# STM32F101_iown register map
Vendor: iown-homecontrol; Series: CM3; File version: 1.3
CPU: CM3 r1p1, little endian, no MPU, no FPU, VTOR, 4 interrupt priority bits
Registers are 32-bit, read-write, reset 0x0 unless marked. A register's access mark holds for its fields unless they carry their own. Offsets are from the block's base; [hi:lo] are bit positions; {n}, {i} and the like mark numbered series.

## TIM6 — Basic timer
Base 0x40001000
Same registers: TIM7 0x40001400
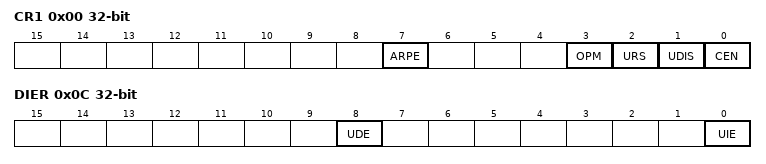
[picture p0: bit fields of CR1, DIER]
0x00 CR1 — control register 1
  [7] ARPE — Auto-reload preload enable
    0=Disabled (TIMx_APRR register is not buffered); 1=Enabled (TIMx_APRR register is buffered)
  [3] OPM — One-pulse mode
    0=Disabled (Counter is not stopped at update event); 1=Enabled (Counter stops counting at the next update event (clearing the CEN bit))
  [2] URS — Update request source
    0=AnyEvent (Any of counter overflow/underflow, setting UG, or update through slave mode, generates an update interrupt or DMA request); 1=CounterOnly (Only counter overflow/underflow generates an update interrupt or DMA request)
  [1] UDIS — Update disable
    0=Enabled (Update event enabled); 1=Disabled (Update event disabled)
  [0] CEN — Counter enable
    0=Disabled (Counter disabled); 1=Enabled (Counter enabled)
0x04 CR2 — control register 2
  [6:4] MMS — Master mode selection
    0=Reset (Use UG bit from TIMx_EGR register); 1=Enable (Use CNT bit from TIMx_CEN register); 2=Update (Use the update event)
0x0C DIER — DMA/Interrupt enable register
  [8] UDE — Update DMA request enable
    0=Disabled (Update DMA request disabled); 1=Enabled (Update DMA request enabled)
  [0] UIE — Update interrupt enable
    0=Disabled (Update interrupt disabled); 1=Enabled (Update interrupt enabled)
0x10 SR — status register
  [0] UIF — Update interrupt flag
    0=Clear (No update occurred); 1=UpdatePending (Update interrupt pending.)
0x14 EGR wo — event generation register
  [0] UG — Update generation
    on write: 1=Update (Re-initializes the timer counter and generates an update of the registers.)
0x24 CNT — counter
  [15:0] CNT — Low counter value
0x28 PSC — prescaler
  [15:0] PSC — Prescaler value
0x2C ARR — auto-reload register
  [15:0] ARR — Low Auto-reload value

## DBGMCU — Debug support
Base 0xE0042000
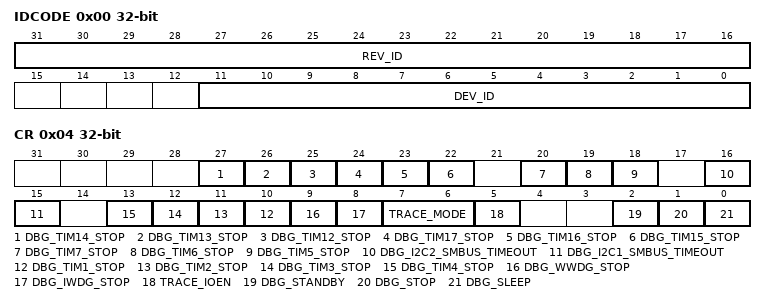
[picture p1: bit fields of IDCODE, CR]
0x00 IDCODE ro — DBGMCU_IDCODE
  [31:16] REV_ID, [11:0] DEV_ID
0x04 CR — DBGMCU_CR
  [27] DBG_TIM14_STOP — TIM14 counter stopped when core is halted
  [26] DBG_TIM13_STOP — TIM13 counter stopped when core is halted
  [25] DBG_TIM12_STOP — TIM12 counter stopped when core is halted
  [24] DBG_TIM17_STOP — TIM17 counter stopped when core is halted
  [23] DBG_TIM16_STOP — TIM16 counter stopped when core is halted
  [22] DBG_TIM15_STOP — TIM15 counter stopped when core is halted
  [20] DBG_TIM7_STOP
  [19] DBG_TIM6_STOP
  [18] DBG_TIM5_STOP
  [16] DBG_I2C2_SMBUS_TIMEOUT
  [15] DBG_I2C1_SMBUS_TIMEOUT
  [n+9] DBG_TIM{n}_STOP (n=1..4)
  [9] DBG_WWDG_STOP
  [8] DBG_IWDG_STOP
  [7:6] TRACE_MODE
  [5] TRACE_IOEN
  [2] DBG_STANDBY
  [1] DBG_STOP
  [0] DBG_SLEEP

## UART4 — Universal asynchronous receiver transmitter
Base 0x40004C00
Same registers: UART5 0x40005000
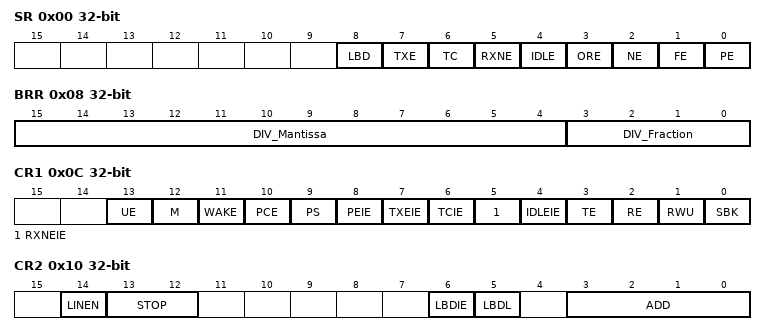
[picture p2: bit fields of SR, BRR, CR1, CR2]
0x00 SR — UART4_SR
  [8] LBD — LIN break detection flag
  [7] TXE ro — Transmit data register empty
  [6] TC — Transmission complete
  [5] RXNE — Read data register not empty
  [4] IDLE ro — IDLE line detected
  [3] ORE ro — Overrun error
  [2] NE ro — Noise error flag
  [1] FE ro — Framing error
  [0] PE ro — Parity error
0x04 DR — UART4_DR
  [8:0] DR
0x08 BRR — UART4_BRR
  [15:4] DIV_Mantissa, [3:0] DIV_Fraction
0x0C CR1 — UART4_CR1
  [13] UE — USART enable
    0=Disabled (USART prescaler and outputs disabled); 1=Enabled (USART enabled)
  [12] M — Word length
    0=8 data bits; 1=9 data bits
  [11] WAKE — Wakeup method
    0=IdleLine (USART wakeup on idle line); 1=AddressMark (USART wakeup on address mark)
  [10] PCE — Parity control enable
    0=Disabled (Parity control disabled); 1=Enabled (Parity control enabled)
  [9] PS — Parity selection
    0=Even parity; 1=Odd (Odd parity)
  [8] PEIE — PE interrupt enable
    0=Disabled (PE interrupt disabled); 1=Enabled (PE interrupt enabled)
  [7] TXEIE — TXE interrupt enable
    0=Disabled (TXE interrupt disabled); 1=Enabled (TXE interrupt enabled)
  [6] TCIE — Transmission complete interrupt enable
    0=Disabled (TC interrupt disabled); 1=Enabled (TC interrupt enabled)
  [5] RXNEIE — RXNE interrupt enable
    0=Disabled (RXNE interrupt disabled); 1=Enabled (RXNE interrupt enabled)
  [4] IDLEIE — IDLE interrupt enable
    0=Disabled (IDLE interrupt disabled); 1=Enabled (IDLE interrupt enabled)
  [3] TE — Transmitter enable
    0=Disabled (Transmitter disabled); 1=Enabled (Transmitter enabled)
  [2] RE — Receiver enable
    0=Disabled (Receiver disabled); 1=Enabled (Receiver enabled)
  [1] RWU — Receiver wakeup
    0=Active (Receiver in active mode); 1=Mute (Receiver in mute mode)
  [0] SBK — Send break
    0=No break character is transmitted; 1=Break character transmitted
0x10 CR2 — UART4_CR2
  [14] LINEN — LIN mode enable
    0=Disabled (LIN mode disabled); 1=Enabled (LIN mode enabled)
  [13:12] STOP — STOP bits
    0=1 stop bit; 2=2 stop bits
  [6] LBDIE — LIN break detection interrupt enable
    0=Disabled (LIN break detection interrupt disabled); 1=Enabled (LIN break detection interrupt enabled)
  [5] LBDL — lin break detection length
    0=10-bit break detection; 1=11-bit break detection
  [3:0] ADD — Address of the USART node
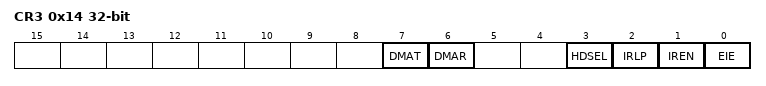
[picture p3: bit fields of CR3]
0x14 CR3 — UART4_CR3
  [7] DMAT — DMA enable transmitter
    0=Disabled (DMA mode is disabled for transmission); 1=Enabled (DMA mode is enabled for transmission)
  [6] DMAR — DMA enable receiver
    0=Disabled (DMA mode is disabled for reception); 1=Enabled (DMA mode is enabled for reception)
  [3] HDSEL — Half-duplex selection
    0=FullDuplex (Half duplex mode is not selected); 1=Half duplex mode is selected
  [2] IRLP — IrDA low-power
    0=Normal mode; 1=Low-power mode
  [1] IREN — IrDA mode enable
    0=Disabled (IrDA disabled); 1=Enabled (IrDA enabled)
  [0] EIE — Error interrupt enable
    0=Disabled (Error interrupt disabled); 1=Enabled (Error interrupt enabled)
